# a34m42x register map
Vendor: ABOV Semiconductor Co., Ltd.; File version: 1.0
ARM 32-bit Cortex-M4F Microcontroller based device, CPU clock up to 140MHz, etc.
CPU: CM4 r0p1, little endian, MPU, FPU, VTOR, 4 interrupt priority bits
Registers are 32-bit, read-write, reset 0x0 unless marked. A register's access mark holds for its fields unless they carry their own. Offsets are from the block's base; lines under a group give offsets from that group; [hi:lo] are bit positions; {n}, {i} and the like mark numbered series; 'fields as' and 'values as' point back to an identical list; <NAME> marks a mode.

## Memory map
0x40000000 SCU size 0x100 — System Control Unit
0x40000200 WDT size 0x100 — WATCH-DOG TIMER
{0x40000400+0x10*n} DMA{n} size 0x10 (n=0..15)
0x40000600 FRT0 size 0x100
0x40000700 FRT1 size 0x100
0x40000A00 RNG size 0x100 — Random Number Generator
0x40001000 PA size 0x100
0x40001100 PB size 0x100
0x40001200 PC size 0x100
0x40001300 PD size 0x100
0x40001400 PE size 0x100
0x40001500 PF size 0x100
0x40001600 PG size 0x100
0x40001FF0 PORTEN size 0xF — General Port Access Enable
{0x40003000+0x40*n} TIMER{n} size 0x40 (n=0..9)
0x40004000 MPWM0 size 0x200
0x40005000 MPWM1 size 0x200
0x40008000 UART0 size 0x100
0x40008100 UART1 size 0x100
0x40008200 UART2 size 0x100
0x40008300 UART3 size 0x100
0x40008400 UART4 size 0x100
0x40008500 UART5 size 0x100
0x40009000 SPI0 size 0x100
0x40009100 SPI1 size 0x100
0x40009200 SPI2 size 0x100
0x4000A000 I2C0 size 0x100
0x4000A100 I2C1 size 0x100
0x4000B000 ADC0 size 0x100
0x4000B100 ADC1 size 0x100
0x4000B200 ADC2 size 0x100
0x4000F000 CHIPCONFIG size 0x10 — Chip Configuration Data
0x41000000 CFMC size 0x1000 — CODE FLASH MEMORY CONTROLLER
0x41001000 DFMC size 0x1000 — DATA FLASH MEMORY CONTROLLER
0x41002000 CRC size 0x1000 — CYCLIC REDUNDANCY CHECK AND CHECKSUM
0x50000400 DMA size 0x10 — Direct Memory Access Control
0x50000600 FRT size 0x100 — Free Run Timer
0x50001000 PCU size 0x100 — General Port
0x50003000 TIMER size 0x40 — TIMER COUNTER
0x50004000 MPWM size 0x200 — Motor Pulse Width Modulation
0x50008000 UART size 0x100 — Universal Asynchronous Receiver/Transmitter
0x50009000 SPI size 0x100 — Serial Peripheral Interface Bus
0x5000A000 I2C size 0x100 — Inter-Integrated Circuit
0x5000B000 ADC size 0x100 — 12-BIT A/D CONVERTER

## Interrupts
0 LVI (SCU)
2 HSEFAIL (SCU)
3 LSEFAIL (SCU)
6 WDT
8 FRT0
9 FRT1
11 CFMC
12 DFMC
{n+15} TIMER{n} (n=0..9)
27 RNG
36 GPIOA (PA)
37 GPIOB (PB)
38 GPIOC (PC)
39 GPIOD (PD)
40 GPIOE (PE)
41 GPIOF (PF)
42 GPIOG (PG)
45 MPWM0PROT (MPWM0)
46 MPWM0OVV (MPWM0)
47 MPWM0U (MPWM0)
48 MPWM0V (MPWM0)
49 MPWM0W (MPWM0)
50 MPWM1PROT (MPWM1)
51 MPWM1OVV (MPWM1)
52 MPWM1U (MPWM1)
53 MPWM1V (MPWM1)
54 MPWM1W (MPWM1)
55 SPI0
56 SPI1
57 SPI2
60 I2C0
61 I2C1
63 UART0
64 UART1
65 UART2
66 UART3
67 UART4
68 UART5
74 ADC0
75 ADC1
76 ADC2
85 CRC

## CHIPCONFIG — Chip Configuration Data
Base 0x4000F000
0x00 VENDORID ro reset 0x41424F56
0x04 CHIPID ro
0x08 REVNR ro — Revision Number Register

## PCU — General Port
Base 0x50001000
Same registers: PA 0x40001000, PB 0x40001100, PC 0x40001200, PD 0x40001300, PE 0x40001400, PF 0x40001500, PG 0x40001600
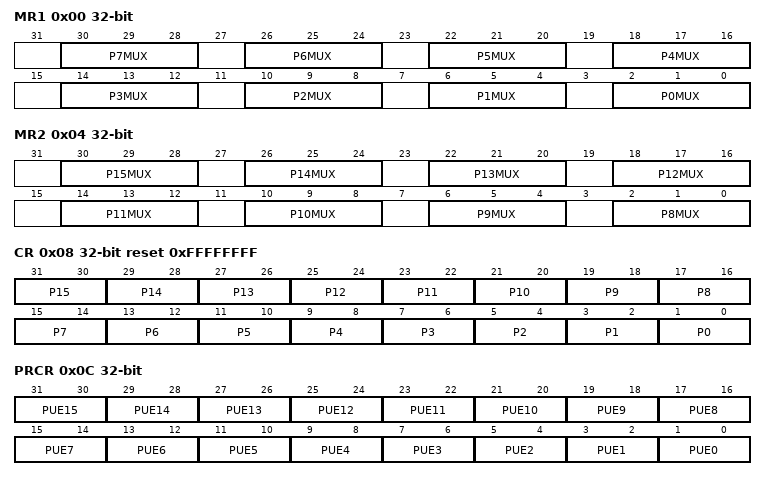
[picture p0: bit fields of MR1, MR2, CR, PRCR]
0x00 MR1 — Port n MUX1 Selection Register
  [4n+2:4n] P{n}MUX (n=0..7) — Pin {n} Mode Selection bits
0x04 MR2 — Port n MUX2 Selection Register
  [4n-30:4n-32] P{n}MUX (n=8..15) — Pin {n} Mode Selection bits
0x08 CR reset 0xFFFFFFFF — Port n Type Selection Register
  [2n+1:2n] P{n} (n=0..15) — Pin {n} Type Selection bit
0x0C PRCR — Port n Pull-up/down Selection Register
  [2n+1:2n] PUE{n} (n=0..15) — Pin {n} Pull-up/down Selection bits
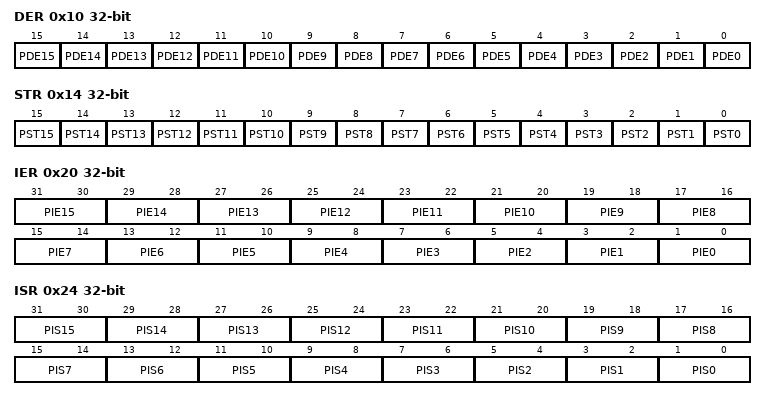
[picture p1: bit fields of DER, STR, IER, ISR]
0x10 DER — Port n Debounce Enable Register
  [n] PDE{n} (n=0..15) — Pin {n} Debounce Enable bits
0x14 STR — Port n Strength Selection Register
  [n] PST{n} (n=0..15) — Pin {n} Strength Selection bit
0x20 IER — Port n Interrupt Enable Register
  [2n+1:2n] PIE{n} (n=0..15) — Pin {n} Interrupt Enable bit
0x24 ISR — Port n Interrupt Status Register
  [2n+1:2n] PIS{n} (n=0..15) — Pin {n} Interrupt Status bit
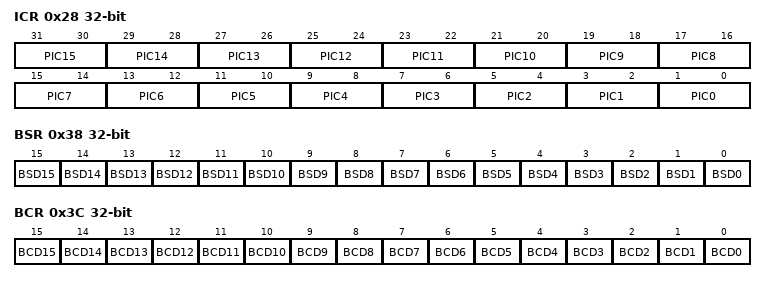
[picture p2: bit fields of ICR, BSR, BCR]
0x28 ICR — Port n Interrupt Control Register
  [2n+1:2n] PIC{n} (n=0..15) — Pin {n} Interrupt Control bit
0x30 ODR — Port n Output Data Register
  [15:0] POD — Pin Output Data bit
0x34 IDR ro — Port n Input Data Register
  [15:0] PID — Port Input Data bits
0x38 BSR wo — Port n Bit Set Register
  [n] BSD{n} (n=0..15) — Port {n} Bit Set bits
0x3C BCR wo — Port n Bit Clear Register
  [n] BCD{n} (n=0..15) — Port {n} Bit Clear bits
